# STM32H7S register map
File version: 1.3
CPU: CM7 r0p1, little endian, MPU, FPU, 4 interrupt priority bits
Registers are 32-bit, read-write, reset 0x0 unless marked. A register's access mark holds for its fields unless they carry their own. Offsets are from the block's base; [hi:lo] are bit positions.

## TIM6 — Basic timers
Base 0x40001000
Same registers: TIM7 0x40001400
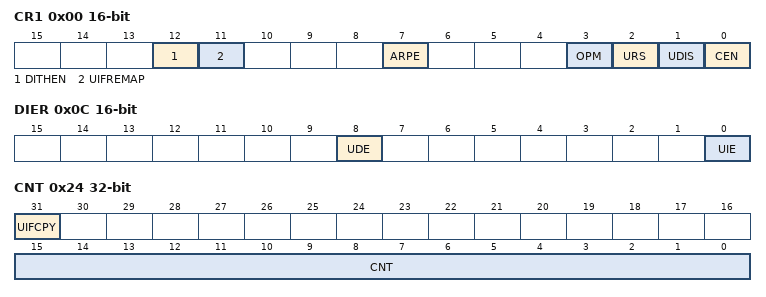
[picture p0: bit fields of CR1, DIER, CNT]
0x00 CR1 16-bit — TIM6 control register 1
  [12] DITHEN — Dithering enable Note: The DITHEN bit can only be modified when CEN bit is reset.
    0=Disabled (Dithering disabled); 1=Enabled (Dithering enabled)
  [11] UIFREMAP — UIF status bit remapping
    0=Disabled (No remapping. UIF status bit is not copied to TIMx_CNT register bit 31); 1=Enabled (Remapping enabled. UIF status bit is copied to TIMx_CNT register bit 31)
  [7] ARPE — Auto-reload preload enable
    0=Disabled (TIMx_APRR register is not buffered); 1=Enabled (TIMx_APRR register is buffered)
  [3] OPM — One-pulse mode
    0=Disabled (Counter is not stopped at update event); 1=Enabled (Counter stops counting at the next update event (clearing the CEN bit))
  [2] URS — Update request source This bit is set and cleared by software to select the UEV event sources. Counter overflow/underflow Setting the UG bit Update generation through the slave mode controller
    0=AnyEvent (Any of counter overflow/underflow, setting UG, or update through slave mode, generates an update interrupt or DMA request); 1=CounterOnly (Only counter overflow/underflow generates an update interrupt or DMA request)
  [1] UDIS — Update disable This bit is set and cleared by software to enable/disable UEV event generation. Counter overflow/underflow Setting the UG bit Update generation through the slave mode controller Buffered registers are then loaded with their preload values.
    0=Enabled (Update event enabled); 1=Disabled (Update event disabled)
  [0] CEN — Counter enable CEN is cleared automatically in one-pulse mode, when an update event occurs.
    0=Disabled (Counter disabled); 1=Enabled (Counter enabled)
0x04 CR2 16-bit — TIM6 control register 2
  [6:4] MMS — Master mode selection These bits are used to select the information to be sent in master mode to slave timers for synchronization (TRGO). The combination is as follows: Note: The clock of the slave timer or he peripheral receiving the tim_trgo must be enabled prior to receive events from the master timer, and must not be changed on-the-fly while triggers are received from the master timer.
    0=Reset (Use UG bit from TIMx_EGR register); 1=Enable (Use CNT bit from TIMx_CEN register); 2=Update (Use the update event)
0x0C DIER 16-bit — TIM6 DMA/Interrupt enable register
  [8] UDE — Update DMA request enable
    0=Disabled (Update DMA request disabled); 1=Enabled (Update DMA request enabled)
  [0] UIE — Update interrupt enable
    0=Disabled (Update interrupt disabled); 1=Enabled (Update interrupt enabled)
0x10 SR 16-bit — TIM6 status register
  [0] UIF write-0-clears — Update interrupt flag This bit is set by hardware on an update event. It is cleared by software. On counter overflow if UDIS = 0 in the TIMx_CR1 register. When CNT is reinitialized by software using the UG bit in the TIMx_EGR register, if URS = 0 and UDIS = 0 in the TIMx_CR1 register.
    on read: 0=NoUpdateOccurred; 1=UpdatePending (Update interrupt pending) | on write: 0=Clear flag
0x14 EGR 16-bit wo — TIM6 event generation register
  [0] UG — Update generation This bit can be set by software, it is automatically cleared by hardware.
    1=Update (Re-initializes the timer counter and generates an update of the registers.)
0x24 CNT access per field — TIM6 counter
  [31] UIFCPY ro — UIF copy This bit is a read-only copy of the UIF bit of the TIMx_ISR register. If the UIFREMAP bit in TIMx_CR1 is reset, bit 31 is reserved and read as 0.
    0=NoUpdateOccurred; 1=UpdatePending (Update interrupt pending)
  [15:0] CNT rw — Counter value Non-dithering mode (DITHEN = 0) The register holds the counter value. Dithering mode (DITHEN = 1) The register only holds the non-dithered part in CNT[15:0]. The fractional part is not available.
0x28 PSC 16-bit — TIM6 prescaler
  [15:0] PSC — Prescaler value The counter clock frequency f<sub>tim_cnt_ck</sub> is equal to f<sub>tim_psc_ck</sub> / (PSC[15:0] + 1). PSC contains the value to be loaded into the active prescaler register at each update event. (including when the counter is cleared through UG bit of TIMx_EGR register.
0x2C ARR reset 0xFFFF — TIM6 auto-reload register
  [19:0] ARR — Auto-reload value ARR is the value to be loaded into the actual auto-reload register. Refer to Section 66.3.4: Time-base unit on page 3923 for more details about ARR update and behavior. The counter is blocked while the auto-reload value is null. Non-dithering mode (DITHEN = 0) The register holds the auto-reload value in ARR[15:0]. The ARR[19:16] bits are reserved. Dithering mode (DITHEN = 1) The register holds the integer part in ARR[19:4]. The ARR[3:0] bitfield contains the dithered part.
